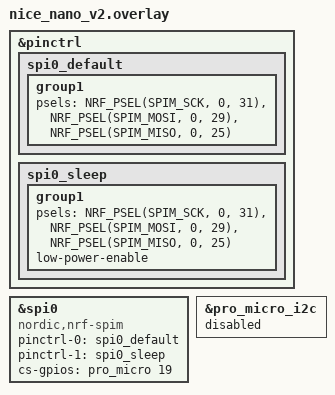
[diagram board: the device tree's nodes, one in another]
/*
 * Copyright (c) 2024 The ZMK Contributors
 *
 * SPDX-License-Identifier: MIT
 */

/*
 * nice-view pins to use:
 *
 * MOSI:  P0.29
 * SCK :  P0.31
 * CA  :  P0.02  (D19) 
 */


&pinctrl {
    spi0_default: spi0_default {
        group1 {
            psels = <NRF_PSEL(SPIM_SCK, 0, 31)>,
                <NRF_PSEL(SPIM_MOSI, 0, 29)>,
                <NRF_PSEL(SPIM_MISO, 0, 25)>;
        };
    };
    spi0_sleep: spi0_sleep {
        group1 {
            psels = <NRF_PSEL(SPIM_SCK, 0, 31)>,
                <NRF_PSEL(SPIM_MOSI, 0, 29)>,
                <NRF_PSEL(SPIM_MISO, 0, 25)>;
            low-power-enable;
        };
    };
};

nice_view_spi: &spi0 {
    compatible = "nordic,nrf-spim";
    pinctrl-0 = <&spi0_default>;
    pinctrl-1 = <&spi0_sleep>;
    pinctrl-names = "default", "sleep";
    cs-gpios = <&pro_micro 19 GPIO_ACTIVE_HIGH>;
};

&pro_micro_i2c {
    status = "disabled";
};
